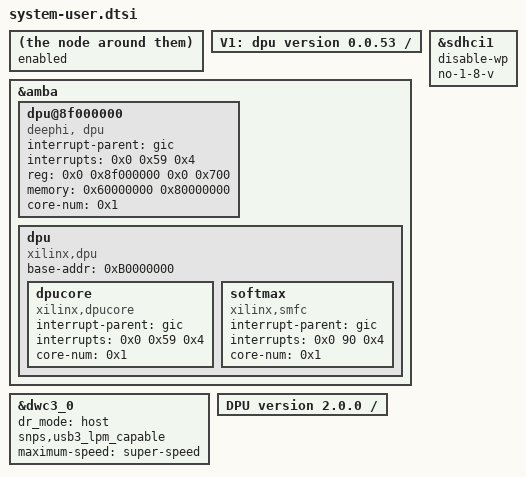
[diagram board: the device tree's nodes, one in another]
V1: dpu version 0.0.53
/include/ "system-conf.dtsi"
/ {
};

&amba{
                dpu@8f000000 {
                        compatible = "deephi, dpu";
                        interrupt-parent = <&gic>;
                        interrupts = <0x0 0x59 0x4 >;
                        reg = <0x0 0x8f000000 0x0 0x700>;
                        memory = <0x60000000 0x80000000>;
                        core-num = <0x1>;
                };
 };

&sdhci1 {
    disable-wp;
    no-1-8-v;
 
};

&dwc3_0 {
    status = "okay";
    dr_mode = "host";
    snps,usb3_lpm_capable;
    phy-names = "usb3-phy";
    maximum-speed = "super-speed";
};

V2: without softmax pl core enabled; DPU version 2.0.0
/include/ "system-conf.dtsi"
/ {
};

&amba {
	dpu {
		#address-cells = <1>;
		#size-cells = <1>;
		compatible = "xilinx,dpu";
		base-addr = <0x81000000>;
	dpucore {
		compatible = "xilinx,dpucore";
		interrupt-parent = <&gic>;
		interrupts = <0x0 59 0x4>;
		core-num = <0x1>;
		};
	};
};

&sdhci1 {
    disable-wp;
    no-1-8-v;
};

&dwc3_0 {
    status = "okay";
    dr_mode = "host";
    snps,usb3_lpm_capable;
    phy-names = "usb3-phy";
    maximum-speed = "super-speed";
};

V3: with softmax pl core enabled; DPU version 2.0.0
/include/ "system-conf.dtsi"
/ {
};

&amba{
	dpu{
	    #address-cells = <1>;
    	    #size-cells = <1>;
    	    compatible = "xilinx,dpu";
    	    base-addr = <0xB0000000>;     //CHANGE THIS ACCORDING TO YOUR DESIGN

	    dpucore {
	        compatible = "xilinx,dpucore";
	        interrupt-parent = <&gic>;
	        interrupts = <0x0 0x59 0x4 >; //CHANGE THIS ACCORDING TO YOUR DESIGN
	        core-num = <0x1>; //CHANGE THIS ACCORDING TO YOUR DESIGN
	    };

	    softmax { 
	        compatible = "xilinx,smfc";
	        interrupt-parent = <&gic>;
	        interrupts = <0x0 90 0x4>;
	        core-num = <0x1>;
	    };

	};
};

&sdhci1 {
    disable-wp;
    no-1-8-v;
};

&dwc3_0 {
    status = "okay";
    dr_mode = "host";
    snps,usb3_lpm_capable;
    phy-names = "usb3-phy";
    maximum-speed = "super-speed";
};
